# STM32G0B1 register map
File version: 1.8
CPU: CM0 r0p1, little endian, MPU, no FPU, 4 interrupt priority bits
Registers are 32-bit, read-write, reset 0x0 unless marked. A register's access mark holds for its fields unless they carry their own. Offsets are from the block's base; [hi:lo] are bit positions; 'fields as' and 'values as' point back to an identical list.

## COMP — Comparator
Base 0x40010200
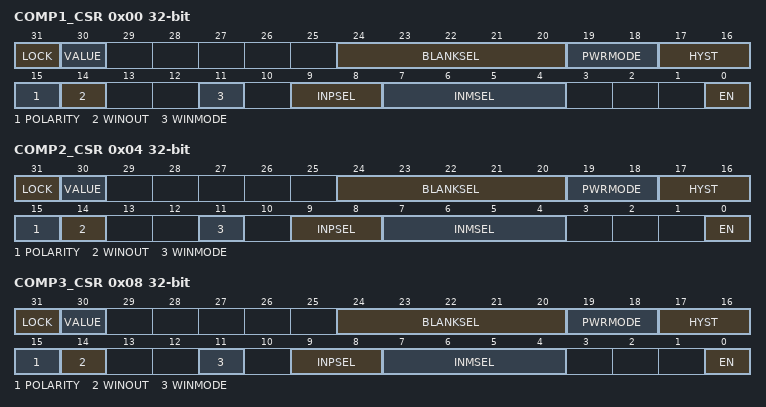
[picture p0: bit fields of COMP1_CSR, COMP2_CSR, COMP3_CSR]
0x00 COMP1_CSR access per field — Comparator 1 control and status register
  [31] LOCK rw — COMP1_CSR register lock This bit is set by software and cleared by a system reset. It locks the whole content of the comparator 1 control register COMP1_CSR[31:0]:
    0=COMP1_CSR[31:0] register read/write bits can be written by software; 1=COMP1_CSR[31:0] register bits can be read but not written by software
  [30] VALUE ro — Comparator 1 output status This bit is read-only. It reflects the level of the comparator 1 output after the polarity selector and blanking, as indicated in .
  [24:20] BLANKSEL rw — Comparator 1 blanking source selector This bitfield is controlled by software (if not locked). It selects the blanking source: xxxx1: TIM1 OC4 xxx1x: TIM1 OC5 xx1xx: TIM2 OC3 x1xxx: TIM3 OC3 1xxxx: TIM15 OC2
    0=None (no blanking)
  [19:18] PWRMODE rw — Comparator 1 power mode selector This bitfield is controlled by software (if not locked). It selects the power consumption and as a consequence the speed of the comparator 1: others: Reserved
    0=High speed; 1=Medium speed
  [17:16] HYST rw — Comparator 1 hysteresis selector This bitfield is controlled by software (if not locked). It selects the hysteresis of the comparator 1:
    0=None; 1=Low; 2=Medium; 3=High
  [15] POLARITY rw — Comparator 1 polarity selector This bit is controlled by software (if not locked). It selects the comparator 1 output polarity:
    0=Non-inverted; 1=Inverted
  [14] WINOUT rw — Comparator 1 output selector This bit is controlled by software (if not locked). It selects the comparator 1 output:
    0=COMP1_VALUE; 1=COMP1_VALUE XOR COMP2_VALUE (required for window mode, see Figure 64)
  [11] WINMODE rw — Comparator 1 non-inverting input selector for window mode This bit is controlled by software (if not locked). It selects the signal for COMP1_INP input of the comparator 1:
    0=Signal selected with INPSEL[1:0] bitfield of this register; 1=COMP2_INP signal of the comparator 2 (required for window mode, see Figure 64)
  [9:8] INPSEL rw — Comparator 1 signal selector for non-inverting input This bitfield is controlled by software (if not locked). It selects the signal for the non-inverting input COMP1_INP of the comparator 1 (also see the WINMODE bit):
    0=PC5; 1=PB2; 2=PA1; 3=None (open)
  [7:4] INMSEL rw — Comparator 1 signal selector for inverting input INM This bitfield is controlled by software (if not locked). It selects the signal for the inverting input COMP1_INM of the comparator 1: > 1000: 1/4 VREFINT
    0=1/4 VREFINT; 1=1/2 VREFINT; 2=3/4 VREFINT; 3=VREFINT; 4=DAC channel 1; 5=DAC channel 2; 6=PB1; 7=PC4; 8=PA0
  [0] EN rw — Comparator 1 enable bit This bit is controlled by software (if not locked). It enables the comparator 1:
    0=Disable; 1=Enable
0x04 COMP2_CSR access per field — Comparator 2 control and status register
  [31] LOCK rw — COMP2_CSR register lock This bit is set by software and cleared by a system reset. It locks the whole content of the comparator 2 control register COMP2_CSR[31:0]:
    0=COMP2_CSR[31:0] register read/write bits can be written by software; 1=COMP2_CSR[31:0] register bits can be read but not written by software
  [30] VALUE ro — Comparator 2 output status This bit is read-only. It reflects the level of the comparator 2 output after the polarity selector and blanking, as indicated in .
  [24:20] BLANKSEL rw — Comparator 2 blanking source selector This bitfield is controlled by software (if not locked). It selects the blanking source: xxxx1: TIM1 OC4 xxx1x: TIM1 OC5 xx1xx: TIM2 OC3 x1xxx: TIM3 OC3 1xxxx: TIM15 OC2
    0=None (no blanking)
  [19:18] PWRMODE rw — Comparator 2 power mode selector This bitfield is controlled by software (if not locked). It selects the power consumption and as a consequence the speed of the comparator 2: others: Reserved
    0=High speed; 1=Medium speed
  [17:16] HYST rw — Comparator 2 hysteresis selector This bitfield is controlled by software (if not locked). It selects the hysteresis of the comparator 2:
    0=None; 1=Low; 2=Medium; 3=High
  [15] POLARITY rw — Comparator 2 polarity selector This bit is controlled by software (if not locked). It selects the comparator 2 output polarity:
    0=Non-inverted; 1=Inverted
  [14] WINOUT rw — Comparator 2 output selector This bit is controlled by software (if not locked). It selects the comparator 2 output:
    0=COMP2_VALUE; 1=COMP1_VALUE XOR COMP2_VALUE (required for window mode, see Figure 64)
  [11] WINMODE rw — Comparator 2 non-inverting input selector for window mode This bit is controlled by software (if not locked). It selects the signal for COMP2_INP input of the comparator 2:
    0=Signal selected with INPSEL[1:0] bitfield of this register; 1=COMP1_INP signal of the comparator 1 (required for window mode, see Figure 64)
  [9:8] INPSEL rw — Comparator 2 signal selector for non-inverting input This bitfield is controlled by software (if not locked). It selects the signal for the non-inverting input COMP2_INP of the comparator 2 (also see the WINMODE bit):
    0=PB4; 1=PB6; 2=PA3; 3=None (open)
  [7:4] INMSEL rw — Comparator 2 signal selector for inverting input INM This bitfield is controlled by software (if not locked). It selects the signal for the inverting input COMP2_INM of the comparator 2: > 1000: 1/4 VREFINT
    0=1/4 VREFINT; 1=1/2 VREFINT; 2=3/4 VREFINT; 3=VREFINT; 4=DAC channel 1; 5=DAC channel 2; 6=PB3; 7=PB7; 8=PA2
  [0] EN rw — Comparator 2 enable bit This bit is controlled by software (if not locked). It enables the comparator 2:
    0=Disable; 1=Enable
0x08 COMP3_CSR access per field — Comparator 2 control and status register
  [31] LOCK rw — COMP3_CSR register lock This bit is set by software and cleared by a system reset. It locks the whole content of the comparator 3 control register COMP3_CSR[31:0]:
    0=COMP3_CSR[31:0] register read/write bits can be written by software; 1=COMP3_CSR[31:0] register bits can be read but not written by software
  [30] VALUE ro — Comparator 3 output status This bit is read-only. It reflects the level of the comparator 2 output after the polarity selector and blanking, as indicated in .
  [24:20] BLANKSEL rw — Comparator 3 blanking source selector This bitfield is controlled by software (if not locked). It selects the blanking source: xxxx1: TIM1 OC4 xxx1x: TIM1 OC5 xx1xx: TIM2 OC3 x1xxx: TIM3 OC3 1xxxx: TIM15 OC2
    0=None (no blanking)
  [19:18] PWRMODE rw — Comparator 3 power mode selector This bitfield is controlled by software (if not locked). It selects the power consumption and as a consequence the speed of the comparator 3: others: Reserved
    0=High speed; 1=Medium speed
  [17:16] HYST rw — Comparator 3 hysteresis selector This bitfield is controlled by software (if not locked). It selects the hysteresis of the comparator 3:
    0=None; 1=Low; 2=Medium; 3=High
  [15] POLARITY rw — Comparator 2 polarity selector This bit is controlled by software (if not locked). It selects the comparator 3 output polarity:
    0=Non-inverted; 1=Inverted
  [14] WINOUT rw — Comparator 3 output selector This bit is controlled by software (if not locked). It selects the comparator 3 output:
    0=COMP2_VALUE; 1=COMP1_VALUE XOR COMP3_VALUE (required for window mode, see Figure 64)
  [11] WINMODE rw — Comparator 3 non-inverting input selector for window mode This bit is controlled by software (if not locked). It selects the signal for COMP3_INP input of the comparator 3:
    values as COMP2_CSR.WINMODE
  [9:8] INPSEL rw — Comparator 3 signal selector for non-inverting input This bitfield is controlled by software (if not locked). It selects the signal for the non-inverting input COMP3_INP of the comparator 3 (also see the WINMODE bit):
    0=PB4; 1=PB6; 2=PA3; 3=None (open)
  [7:4] INMSEL rw — Comparator 3 signal selector for inverting input INM This bitfield is controlled by software (if not locked). It selects the signal for the inverting input COMP3_INM of the comparator 3: > 1000: 1/4 VREFINT
    values as COMP2_CSR.INMSEL
  [0] EN rw — Comparator 3 enable bit This bit is controlled by software (if not locked). It enables the comparator 3:
    0=Disable; 1=Enable

## Notices in the file
Copyright (c) 2024 STMicroelectronics.
SPDX-License-Identifier: Apache-2.0
Licensed under the Apache License, Version 2.0 (the "License");
you may not use this file except in compliance with the License.
You may obtain a copy of the License at
http://www.apache.org/licenses/LICENSE-2.0
Unless required by applicable law or agreed to in writing, software
distributed under the License is distributed on an "AS IS" BASIS,
WITHOUT WARRANTIES OR CONDITIONS OF ANY KIND, either express or implied.
See the License for the specific language governing permissions and
limitations under the License.
